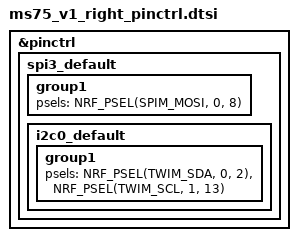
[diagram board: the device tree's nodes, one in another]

&pinctrl {
    spi3_default: spi3_default {
        group1 {
            psels = <NRF_PSEL(SPIM_MOSI, 0, 8)>;
        };

	i2c0_default: i2c0_default {
		group1 {
			psels = <NRF_PSEL(TWIM_SDA, 0, 2)>,
				    <NRF_PSEL(TWIM_SCL, 1, 13)>;
			};
		};
	};
};
